# ESP32-S31 register map
Vendor: ESPRESSIF SYSTEMS (SHANGHAI) CO., LTD.; Series: ESP32 S-Series; File version: 1
CPU: RV32IMAFC r0p0, little endian, no MPU, FPU, 0 interrupt priority bits
Address unit: 32 bits
Registers are 32-bit, read-write, reset 0x0 unless marked. A register's access mark holds for its fields unless they carry their own. Offsets are from the block's base; [hi:lo] are bit positions; {n}, {i} and the like mark numbered series; 'fields as' and 'values as' point back to an identical list.

## USB_OTG_HS (part 5 of 5) — USB_OTG_HS Peripheral
Base 0x20300000
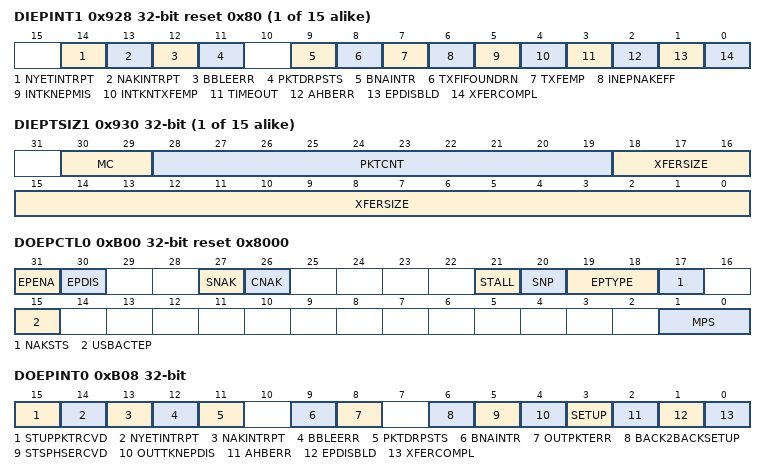
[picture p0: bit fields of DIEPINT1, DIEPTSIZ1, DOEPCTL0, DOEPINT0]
{0x908+0x20*i} DIEPINT{i} access per field reset 0x80 (i=1..15) — This register contains the interrupts for the IN Endpoint {i} of the Device controller. Note: This register exists for an endpoint i if the OTG_EP_DIR_i parameter is 0 or 1 for that endpoint.
  [14] NYETINTRPT rw — NYET Interrupt (NYETIntrpt) The core generates this interrupt when a NYET response is transmitted for a non isochronous OUT endpoint.
  [13] NAKINTRPT rw — NAK Interrupt (NAKInterrupt) The core generates this interrupt when a NAK is transmitted or received by the device. In case of isochronous IN endpoints the interrupt gets generated when a zero length packet is transmitted due to un-availability of data in the TXFifo.
  [12] BBLEERR rw — NAK Interrupt (BbleErr) The core generates this interrupt when babble is received for the endpoint.
  [11] PKTDRPSTS rw — Packet Drop Status (PktDrpSts) This bit indicates to the application that an ISOC OUT packet has been dropped. This bit does not have an associated mask bit and does not generate an interrupt. Dependency: This bit is valid in non Scatter/Gather DMA mode when periodic transfer interrupt feature is selected.
  [9] BNAINTR rw — BNA (Buffer Not Available) Interrupt (BNAIntr) This bit is valid only when Scatter/Gather DMA mode is enabled. The core generates this interrupt when the descriptor accessed is not ready for the Core to process, such as Host busy or DMA done.
  [8] TXFIFOUNDRN rw — Fifo Underrun (TxfifoUndrn) Applies to IN endpoints Only This bit is valid only If thresholding is enabled. The core generates this interrupt when it detects a transmit FIFO underrun condition for this endpoint.
  [7] TXFEMP ro — Transmit FIFO Empty (TxFEmp) This bit is valid only for IN endpoints This interrupt is asserted when the TxFIFO for this endpoint is either half or completely empty. The half or completely empty status is determined by the TxFIFO Empty Level bit in the Core AHB Configuration register (GAHBCFG.NPTxFEmpLvl)).
  [6] INEPNAKEFF rw — IN Endpoint NAK Effective (INEPNakEff) Applies to periodic IN endpoints only. This bit can be cleared when the application clears the IN endpoint NAK by writing to DIEPCTLn.CNAK. This interrupt indicates that the core has sampled the NAK bit Set (either by the application or by the core). The interrupt indicates that the IN endpoint NAK bit Set by the application has taken effect in the core. This interrupt does not guarantee that a NAK handshake is sent on the USB. A STALL bit takes priority over a NAK bit.
  [5] INTKNEPMIS rw — IN Token Received with EP Mismatch (INTknEPMis) Applies to non-periodic IN endpoints only. Indicates that the data in the top of the non-periodic TxFIFO belongs to an endpoint other than the one for which the IN token was received. This interrupt is asserted on the endpoint for which the IN token was received.
  [4] INTKNTXFEMP rw — IN Token Received When TxFIFO is Empty (INTknTXFEmp) Applies to non-periodic IN endpoints only. Indicates that an IN token was received when the associated TxFIFO (periodic/non-periodic) was empty. This interrupt is asserted on the endpoint for which the IN token was received.
  [3] TIMEOUT rw — Timeout Condition (TimeOUT) - In shared TX FIFO mode, applies to non-isochronous IN endpoints only. - In dedicated FIFO mode, applies only to Control IN endpoints. - In Scatter/Gather DMA mode, the TimeOUT interrupt is not asserted. Indicates that the core has detected a timeout condition on the USB for the last IN token on this endpoint.
  [2] AHBERR rw — AHB Error (AHBErr) Applies to IN and OUT endpoints. This is generated only in Internal DMA mode when there is an AHB error during an AHB read/write. The application can read the corresponding endpoint DMA address register to get the error address. For details, see AHB Error Handling in the Programming Guide.
  [1] EPDISBLD rw — Endpoint Disabled Interrupt (EPDisbld) Applies to IN and OUT endpoints. This bit indicates that the endpoint is disabled per the application's request.
  [0] XFERCOMPL rw — Transfer Completed Interrupt (XferCompl) Applies to IN and OUT endpoints. - When Scatter/Gather DMA mode is enabled -- For IN endpoint this field indicates that the requested data from the descriptor is moved from external system memory to internal FIFO. -- For OUT endpoint this field indicates that the requested data from the internal FIFO is moved to external system memory. This interrupt is generated only when the corresponding endpoint descriptor is closed, and the IOC bit for the corresponding descriptor is set. - When Scatter/Gather DMA mode is disabled, this field indicates that the programmed transfer is complete on the AHB as well as on the USB, for this endpoint.
{0x910+0x20*i} DIEPTSIZ{i} (i=1..15) — This register reflects the Transfer Size of the IN Endpoint {i} of the Device controller. Note: This register exists for an endpoint i if the OTG_EP_DIR_i parameter is 0 or 1 for that endpoint.
  [30:29] MC — MC Applies to IN endpoints only. For periodic IN endpoints, this field indicates the number of packets that must be transmitted per microframe on the USB. The core uses this field to calculate the data PID for isochronous IN endpoints. - 2'b01: 1 packet - 2'b10: 2 packets - 2'b11: 3 packets For non-periodic IN endpoints, this field is valid only in Internal DMA mode. It specifies the number of packets the core must fetchfor an IN endpoint before it switches to the endpoint pointed to by the Next Endpoint field of the Device Endpoint-n Control register (DIEPCTLn.NextEp)
  [28:19] PKTCNT — Packet Count (PktCnt) Indicates the total number of USB packets that constitute the Transfer Size amount of data for endpoint 0. This field is decremented every time a packet (maximum size or short packet) is read from the TxFIFO.
  [18:0] XFERSIZE — Transfer Size (XferSize) Indicates the transfer size in bytes for the endpoint. The core interrupts the application only after it has exhausted the transfer size amount of data. The transfer size can be Set to the maximum packet size of the endpoint, to be interrupted at the end of each packet. The core decrements this field every time a packet from the external memory is written to the TxFIFO.
{0x914+0x20*i} DIEPDMA{i} (i=1..15) — This register contains the DMA Address for the IN Endpoint {i} of the Device controller. Note: This register exists for an endpoint i if the OTG_EP_DIR_i parameter is 0 or 1 for that endpoint.
  [31:0] DMAADDR — Holds the start address of the external memory for storing or fetching endpoint data. Note: For control endpoints, this field stores control OUT data packets as well as SETUP transaction data packets. When more than three SETUP packets are received back-to-back, the SETUP data packet in the memory is overwritten. This register is incremented on every AHB transaction. The application can give only a DWORD-aligned address. - When Scatter/Gather DMA mode is not enabled, the application programs the start address value in this field. - When Scatter/Gather DMA mode is enabled, this field indicates the base pointer for the descriptor list.
{0x918+0x20*i} DTXFSTS{i} ro reset 0x400 (i=1..15) — This register reflects the status of the IN Endpoint Transmit FIFO Status Register {i} of the Device controller. Note: This register exists for an endpoint i if the OTG_EP_DIR_i parameter is 0 or 1 for that endpoint.
  [15:0] INEPTXFSPCAVAIL — IN Endpoint TxFIFO Space Avail (INEPTxFSpcAvail) Indicates the amount of free space available in the Endpoint TxFIFO. Values are in terms of 32-bit words. - 16'h0: Endpoint TxFIFO is full - 16'h1: 1 word available - 16'h2: 2 words available - 16'hn: n words available (where 0 n 32,768) - 16'h8000: 32,768 words available - Others: Reserved In DRD configurations (OTG_MODE = 0, 1, or 2) with dynamic fifo sizing feature enabled (OTG_DFIFO_DYNAMIC=1), the value of this field is, - the maximum value of (OTG_TX_HNPERIO_DFIFO_DEPTH, OTG_TX_DINEP_DFIFO_DEPTH_0) during reset, and - OTG_TX_DINEP_DFIFO_DEPTH_0, immediately after reset deassertion
{0x91C+0x20*i} DIEPDMAB{i} ro (i=1..15) — This register contains the DMA Buffer Address of the IN Endpoint {i} of the Device controller. Note: This register exists for an endpoint i if the OTG_EP_DIR_i parameter is 0 or 1 for that endpoint.
  [31:0] DMABUFFERADDR — Holds the current buffer address.This register is updated as and when the data transfer for the corresponding end point is in progress. This register is present only in Scatter/Gather DMA mode. Otherwise this field is reserved.
0xB00 DOEPCTL0 access per field reset 0x8000 — This register is used to control the characteristics of the OUT Endpoint 0 of the Device controller.
  [31] EPENA rw — Endpoint Enable (EPEna) - When Scatter/Gather DMA mode is enabled, for OUT endpoints this bit indicates that the descriptor structure and data buffer to receive data is setup. - When Scatter/Gather DMA mode is disabled (such as for buffer-pointer based DMA mode)this bit indicates that the application has allocated the memory to start receiving data from the USB. - The core clears this bit before setting any of the following interrupts on this endpoint: -- SETUP Phase Done -- Endpoint Disabled -- Transfer Completed Note: In DMA mode, this bit must be set for the core to transfer SETUP data packets into memory and it is not cleared on Transfer Completed interrupt of SETUP packet.
  [30] EPDIS ro — Endpoint Disable (EPDis) The application cannot disable control OUT endpoint 0.
  [27] SNAK rw — Set NAK (SNAK) A write to this bit sets the NAK bit for the endpoint. Using this bit, the application can control the transmission of NAK handshakes on an endpoint. The core can also set bit on a Transfer Completed interrupt, or after a SETUP is received on the endpoint.
  [26] CNAK rw — Clear NAK (CNAK) A write to this bit clears the NAK bit for the endpoint.
  [21] STALL rw — STALL Handshake (Stall) The application can only set this bit, and the core clears it, when a SETUP token is received for this endpoint. If a NAK bit or Global OUT NAK is Set along with this bit, the STALL bit takes priority. Irrespective of this bit's setting, the core always responds to SETUP data packets with an ACK handshake.
  [20] SNP rw — RESERVED
  [19:18] EPTYPE ro — Endpoint Type (EPType) Hardcoded to 2'b00 for control.
  [17] NAKSTS ro — NAK Status (NAKSts) Indicates the following: - 1'b0: The core is transmitting non-NAK handshakes based on the FIFO status. - 1'b1: The core is transmitting NAK handshakes on this endpoint. When either the application or the core sets this bit, the core stops receiving data, even If there is space in the RxFIFO to accommodate the incoming packet. Irrespective of this bit's setting, the core always responds to SETUP data packets with an ACK handshake.
  [15] USBACTEP ro — USB Active Endpoint (USBActEP) This bit is always set to 1, indicating that a control endpoint 0 is always active in all configurations and interfaces.
  [1:0] MPS ro — Maximum Packet Size (MPS) The maximum packet size for control OUT endpoint 0 is the same as what is programmed in control IN Endpoint 0. - 2'b00: 64 bytes - 2'b01: 32 bytes - 2'b10: 16 bytes - 2'b11: 8 bytes
0xB08 DOEPINT0 — This register contains the interrupts for the OUT Endpoint 0 of the Device controller.
  [15] STUPPKTRCVD — Setup Packet Received Applicable for Control OUT Endpoints in only in the Buffer DMA Mode Set by the controller, this bit indicates that this buffer holds 8 bytes of setup data. There is only one Setup packet per buffer. On receiving a Setup packet, the controller closes the buffer and disables the corresponding endpoint. The application has to re-enable the endpoint to receive any OUT data for the Control Transfer and reprogram the buffer start address. Note: Because of the above behavior, the controller can receive any number of back to back setup packets and one buffer for every setup packet is used. - 1'b0: No Setup packet received - 1'b1: Setup packet received Reset: 1'b0
  [14] NYETINTRPT — NYET Interrupt (NYETIntrpt) The core generates this interrupt when a NYET response is transmitted for a non isochronous OUT endpoint.
  [13] NAKINTRPT — NAK Interrupt (NAKInterrupt) The core generates this interrupt when a NAK is transmitted or received by the device. In case of isochronous IN endpoints the interrupt gets generated when a zero length packet is transmitted due to un-availability of data in the TXFifo.
  [12] BBLEERR — NAK Interrupt (BbleErr) The core generates this interrupt when babble is received for the endpoint.
  [11] PKTDRPSTS — Packet Drop Status (PktDrpSts) This bit indicates to the application that an ISOC OUT packet has been dropped. This bit does not have an associated mask bit and does not generate an interrupt. Dependency: This bit is valid in non Scatter/Gather DMA mode when periodic transfer interrupt feature is selected.
  [9] BNAINTR — BNA (Buffer Not Available) Interrupt (BNAIntr) This bit is valid only when Scatter/Gather DMA mode is enabled. The core generates this interrupt when the descriptor accessed is not ready for the core to process, such as Host busy or DMA done.
  [8] OUTPKTERR — OUT Packet Error (OutPktErr) Applies to OUT endpoints Only This interrupt is valid only when thresholding is enabled. This interrupt is asserted when the core detects an overflow or a CRC error for non-Isochronous OUT packet.
  [6] BACK2BACKSETUP — Back-to-Back SETUP Packets Received (Back2BackSETup) Applies to Control OUT endpoints only. This bit indicates that the core has received more than three back-to-back SETUP packets for this particular endpoint. For information about handling this interrupt,
  [5] STSPHSERCVD — Status Phase Received for Control Write (StsPhseRcvd) This interrupt is valid only for Control OUT endpoints. This interrupt is generated only after the core has transferred all the data that the host has sent during the data phase of a control write transfer, to the system memory buffer. The interrupt indicates to the application that the host has switched from data phase to the status phase of a Control Write transfer. The application can use this interrupt to ACK or STALL the Status phase, after it has decoded the data phase.
  [4] OUTTKNEPDIS — OUT Token Received When Endpoint Disabled (OUTTknEPdis) Applies only to control OUT endpoints. Indicates that an OUT token was received when the endpoint was not yet enabled. This interrupt is asserted on the endpoint for which the OUT token was received.
  [3] SETUP — SETUP Phase Done (SetUp) Applies to control OUT endpoints only. Indicates that the SETUP phase for the control endpoint is complete and no more back-to-back SETUP packets were received for the current control transfer. On this interrupt, the application can decode the received SETUP data packet.
  [2] AHBERR — AHB Error (AHBErr) Applies to IN and OUT endpoints. This is generated only in Internal DMA mode when there is an AHB error during an AHB read/write. The application can read the corresponding endpoint DMA address register to get the error address. For details, see AHB Error Handling section in the Programming Guide.
  [1] EPDISBLD — Endpoint Disabled Interrupt (EPDisbld) Applies to IN and OUT endpoints. This bit indicates that the endpoint is disabled per the application's request.
  [0] XFERCOMPL — Transfer Completed Interrupt (XferCompl) Applies to IN and OUT endpoints. When Scatter/Gather DMA mode is enabled - For IN endpoint this field indicates that the requested data from the descriptor is moved from external system memory to internal FIFO. - For OUT endpoint this field indicates that the requested data from the internal FIFO is moved to external system memory. This interrupt is generated only when the corresponding endpoint descriptor is closed, and the IOC bit for the corresponding descriptor is Set. Note: In DMA mode, this bit must be set for the core to transfer SETUP data packets into memory. When Scatter/Gather DMA mode is disabled, this field indicates that the programmed transfer is complete on the AHB as well as on the USB, for this endpoint.
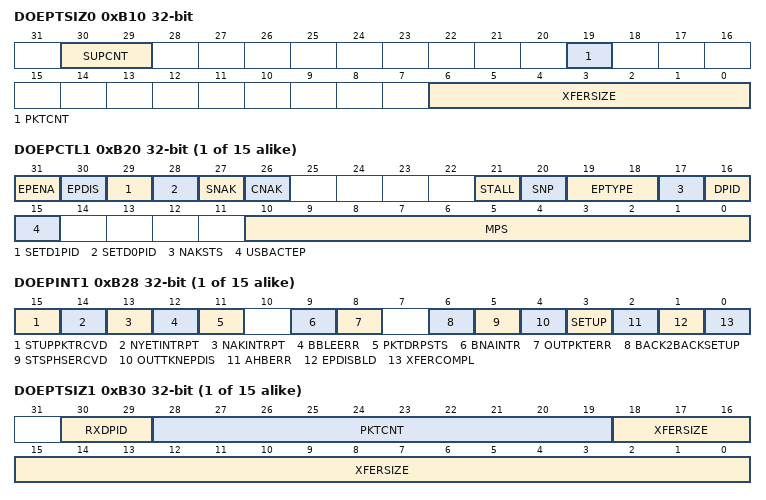
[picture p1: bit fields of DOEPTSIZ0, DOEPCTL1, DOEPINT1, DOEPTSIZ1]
0xB10 DOEPTSIZ0 — This register contains the Transfer Size for the OUT Endpoint 0 of the Device controller.
  [30:29] SUPCNT — SETUP Packet Count (SUPCnt) This field specifies the number of back-to-back SETUP data packets the endpoint can receive. - 2'b01: 1 packet - 2'b10: 2 packets - 2'b11: 3 packets
  [19] PKTCNT — Packet Count (PktCnt) This field is decremented to zero after a packet is written into the RxFIFO.
  [6:0] XFERSIZE — Transfer Size (XferSize) Indicates the transfer size in bytes for endpoint 0. The core interrupts the application only after it has exhausted the transfer size amount of data. The transfer size can be Set to the maximum packet size of the endpoint, to be interrupted at the end of each packet. The core decrements this field every time a packet is read from the RxFIFO and written to the external memory.
{0xB14+0x20*i} DOEPDMA{i} (i=0..15) — This register contains the DMA Address for the OUT Endpoint {i} of the Device controller.
  fields as DIEPDMA1
{0xB1C+0x20*i} DOEPDMAB{i} ro (i=0..15) — This register contains the DMA Buffer Address for the OUT Endpoint {i} of the Device controller.
  fields as DIEPDMAB1
{0xB00+0x20*i} DOEPCTL{i} access per field (i=1..15) — This register is used to control the characteristics of OUT Endpoint {i} of the Device controller.
  [31] EPENA rw — Endpoint Enable (EPEna) Applies to IN and OUT endpoints. When Scatter/Gather DMA mode is enabled, - For IN endpoints this bit indicates that the descriptor structure and data buffer with data ready to transmit is setup. - For OUT endpoint it indicates that the descriptor structure and data buffer to receive data is setup. When Scatter/Gather DMA mode is enabled such as for buffer-pointer based DMA mode: - For IN endpoints, this bit indicates that data is ready to be transmitted on the endpoint. - For OUT endpoints, this bit indicates that the application has allocated the memory to start receiving data from the USB. The core clears this bit before setting any of the following interrupts on this endpoint: - SETUP Phase Done - Endpoint Disabled - Transfer Completed Note: For control endpoints in DMA mode, this bit must be set for the controller to transfer SETUP data packets to the memory. This bit is not cleared on Transfer Completed interrupt of the SETUP packet.
  [30] EPDIS rw — Endpoint Disable (EPDis) Applies to IN and OUT endpoints. The application sets this bit to stop transmitting/receiving data on an endpoint, even before the transfer for that endpoint is complete. The application must wait for the Endpoint Disabled interrupt before treating the endpoint as disabled. The core clears this bit before setting the Endpoint Disabled interrupt. The application must set this bit only if Endpoint Enable is already set for this endpoint.
  [29] SETD1PID rw — Set DATA1 PID (SetD1PID) - Applies to interrupt and bulk IN and OUT endpoints only. - Writing to this field sets the Endpoint Data PID (DPID) field in this register to DATA1. - This field is applicable both for scatter-gather DMA mode and non scatter-gather DMA mode. Reset: 1'b0 Set Odd (micro)frame (SetOddFr) - Applies to isochronous IN and OUT endpoints only. - Writing to this field sets the even and odd (micro)frame (EO_FrNum) field to odd (micro)frame. Reset: 1'b0
  [28] SETD0PID rw — Set DATA0 PID (SetD0PID) - Applies to interrupt/bulk IN and OUT endpoints only. - Writing to this field sets the Endpoint Data PID (DPID) field in this register to DATA0. - This field is applicable both for Scatter/Gather DMA mode and non-Scatter/Gather DMA mode. Reset: 1'b0 In non-Scatter/Gather DMA mode: Set Even (micro)frame (SetEvenFr) - Applies to isochronous IN and OUT endpoints only. - Writing to this field sets the Even/Odd (micro)frame (EO_FrNum) field to even (micro)frame. - When Scatter/Gather DMA mode is enabled, this field is reserved. The frame number in which to send data is in the transmit descriptor structure. The frame in which to receive data is updated in receive descriptor structure. Reset: 1'b0
  [27] SNAK rw — Set NAK (SNAK) A write to this bit sets the NAK bit for the endpoint. Using this bit, the application can control the transmission of NAK handshakes on an endpoint. The core can also set this bit for an endpoint after a SETUP packet is received on that endpoint.
  [26] CNAK rw — Clear NAK (CNAK) A write to this bit clears the NAK bit for the endpoint.
  [21] STALL rw — STALL Handshake (Stall) Applies to non-control, non-isochronous IN and OUT endpoints only. The application sets this bit to stall all tokens from the USB host to this endpoint. If a NAK bit, Global Non-periodic IN NAK, or Global OUT NAK is set along with this bit, the STALL bit takes priority. Only the application can clear this bit, never the core. Applies to control endpoints only. The application can only set this bit, and the core clears it, when a SETUP token is received for this endpoint. If a NAK bit, Global Non-periodic IN NAK, or Global OUT NAK is set along with this bit, the STALL bit takes priority. Irrespective of this bit's setting, the core always responds to SETUP data packets with an ACK handshake.
  [20] SNP rw — RESERVED
  [19:18] EPTYPE rw — Endpoint Type (EPType) This is the transfer type supported by this logical endpoint. - 2'b00: Control - 2'b01: Isochronous - 2'b10: Bulk - 2'b11: Interrupt
  [17] NAKSTS ro — NAK Status (NAKSts) Indicates the following: - 1'b0: The core is transmitting non-NAK handshakes based on the FIFO status. - 1'b1: The core is transmitting NAK handshakes on this endpoint. When either the application or the core sets this bit: - The core stops receiving any data on an OUT endpoint, even if there is space in the RxFIFO to accommodate the incoming packet. - For non-isochronous IN endpoints: The core stops transmitting any data on an IN endpoint, even if there data is available in the TxFIFO. - For isochronous IN endpoints: The core sends out a zero-length data packet, even if there data is available in the TxFIFO. Irrespective of this bit's setting, the core always responds to SETUP data packets with an ACK handshake.
  [16] DPID ro — Endpoint Data PID (DPID) Applies to interrupt/bulk IN and OUT endpoints only. Contains the PID of the packet to be received or transmitted on this endpoint. The application must program the PID of the first packet to be received or transmitted on this endpoint, after the endpoint is activated. The applications use the SetD1PID and SetD0PID fields of this register to program either DATA0 or DATA1 PID. - 1'b0: DATA0 - 1'b1: DATA1 This field is applicable for both Scatter/Gather DMA mode and non-Scatter/Gather DMA mode. Reset: 1'b0 Even/Odd (Micro)Frame (EO_FrNum) In non-Scatter/Gather DMA mode: - Applies to isochronous IN and OUT endpoints only. - Indicates the (micro)frame number in which the core transmits/receives isochronous data for this endpoint. The application must program the even/odd (micro)frame number in which it intends to transmit/receive isochronous data for this endpoint using the SetEvnFr and SetOddFr fields in this register. -- 1'b0: Even (micro)frame -- 1'b1: Odd (micro)frame - When Scatter/Gather DMA mode is enabled, this field is reserved. The frame number in which to send data is provided in the transmit descriptor structure. The frame in which data is received is updated in receive descriptor structure. Reset: 1'b0
  [15] USBACTEP rw — USB Active Endpoint (USBActEP) Indicates whether this endpoint is active in the current configuration and interface. The core clears this bit for all endpoints (other than EP 0) after detecting a USB reset. After receiving the SetConfiguration and SetInterface commands, the application must program endpoint registers accordingly and set this bit.
  [10:0] MPS rw — Maximum Packet Size (MPS) The application must program this field with the maximum packet size for the current logical endpoint. This value is in bytes.
{0xB08+0x20*i} DOEPINT{i} (i=1..15) — This register contains the interrupts for the OUT Endpoint {i} of the Device controller.
  [15] STUPPKTRCVD — Setup Packet Received Applicable for Control OUT Endpoints in only in the Buffer DMA Mode Set by the controller, this bit indicates that this buffer holds 8 bytes of setup data. There is only one Setup packet per buffer. On receiving a Setup packet, the controller closes the buffer and disables the corresponding endpoint. The application has to re-enable the endpoint to receive any OUT data for the Control Transfer and reprogram the buffer start address. Note: Because of the above behavior, the controller can receive any number of back to back setup packets and one buffer for every setup packet is used. - 1'b0: No Setup packet received - 1'b1: Setup packet received Reset: 1'b0
  [14] NYETINTRPT — NYET Interrupt (NYETIntrpt) The core generates this interrupt when a NYET response is transmitted for a non isochronous OUT endpoint.
  [13] NAKINTRPT — NAK Interrupt (NAKInterrupt) The core generates this interrupt when a NAK is transmitted or received by the device. In case of isochronous IN endpoints the interrupt gets generated when a zero length packet is transmitted due to un-availability of data in the TXFifo.
  [12] BBLEERR — NAK Interrupt (BbleErr) The core generates this interrupt when babble is received for the endpoint.
  [11] PKTDRPSTS — Packet Drop Status (PktDrpSts) This bit indicates to the application that an ISOC OUT packet has been dropped. This bit does not have an associated mask bit and does not generate an interrupt. Dependency: This bit is valid in non Scatter/Gather DMA mode when periodic transfer interrupt feature is selected.
  [9] BNAINTR — BNA (Buffer Not Available) Interrupt (BNAIntr) This bit is valid only when Scatter/Gather DMA mode is enabled. The core generates this interrupt when the descriptor accessed is not ready for the Core to process, such as Host busy or DMA done
  [8] OUTPKTERR — OUT Packet Error (OutPktErr) Applies to OUT endpoints Only This interrupt is valid only when thresholding is enabled. This interrupt is asserted when the core detects an overflow or a CRC error for non-Isochronous OUT packet.
  [6] BACK2BACKSETUP — Back-to-Back SETUP Packets Received (Back2BackSETup) Applies to Control OUT endpoints only. This bit indicates that the core has received more than three back-to-back SETUP packets for this particular endpoint. For information about handling this interrupt,
  [5] STSPHSERCVD — Status Phase Received for Control Write (StsPhseRcvd) This interrupt is valid only for Control OUT endpoints. This interrupt is generated only after the core has transferred all the data that the host has sent during the data phase of a control write transfer, to the system memory buffer. The interrupt indicates to the application that the host has switched from data phase to the status phase of a Control Write transfer. The application can use this interrupt to ACK or STALL the Status phase, after it has decoded the data phase.
  [4] OUTTKNEPDIS — OUT Token Received When Endpoint Disabled (OUTTknEPdis) Applies only to control OUT endpoints. Indicates that an OUT token was received when the endpoint was not yet enabled. This interrupt is asserted on the endpoint for which the OUT token was received.
  [3] SETUP — SETUP Phase Done (SetUp) Applies to control OUT endpoints only. Indicates that the SETUP phase for the control endpoint is complete and no more back-to-back SETUP packets were received for the current control transfer. On this interrupt, the application can decode the received SETUP data packet.
  [2] AHBERR — AHB Error (AHBErr) Applies to IN and OUT endpoints. This is generated only in Internal DMA mode when there is an AHB error during an AHB read/write. The application can read the corresponding endpoint DMA address register to get the error address. For details, see AHB Error Handling section in the Programming Guide.
  [1] EPDISBLD — Endpoint Disabled Interrupt (EPDisbld) Applies to IN and OUT endpoints. This bit indicates that the endpoint is disabled per the application's request.
  [0] XFERCOMPL — Transfer Completed Interrupt (XferCompl) Applies to IN and OUT endpoints. - When Scatter/Gather DMA mode is enabled -- For IN endpoint this field indicates that the requested data from the descriptor is moved from external system memory to internal FIFO. -- For OUT endpoint this field indicates that the requested data from the internal FIFO is moved to external system memory. This interrupt is generated only when the corresponding endpoint descriptor is closed, and the IOC bit for the corresponding descriptor is Set. - When Scatter/Gather DMA mode is disabled, this field indicates that the programmed transfer is complete on the AHB as well as on the USB, for this endpoint.
{0xB10+0x20*i} DOEPTSIZ{i} access per field (i=1..15) — This register contains the Transfer Size for the OUT Endpoint {i} of the Device controller.
  [30:29] RXDPID ro — RxDPID Applies to isochronous OUT endpoints only. This is the data PID received in the last packet for this endpoint. - 2'b00: DATA0 - 2'b01: DATA2 - 2'b10: DATA1 - 2'b11: MDATA SETUP Packet Count (SUPCnt) Applies to control OUT Endpoints only. This field specifies the number of back-to-back SETUP data packets the endpoint can receive. - 2'b01: 1 packet - 2'b10: 2 packets - 2'b11: 3 packets
  [28:19] PKTCNT rw — Packet Count (PktCnt) This field is decremented to zero after a packet is written into the RxFIFO.
  [18:0] XFERSIZE rw — Transfer Size (XferSize) Indicates the transfer size in bytes for the endpoint. The core interrupts the application only after it has exhausted the transfer size amount of data. The transfer size can be Set to the maximum packet size of the endpoint, to be interrupted at the end of each packet. The core decrements this field every time a packet is read from the RxFIFO and written to the external memory.
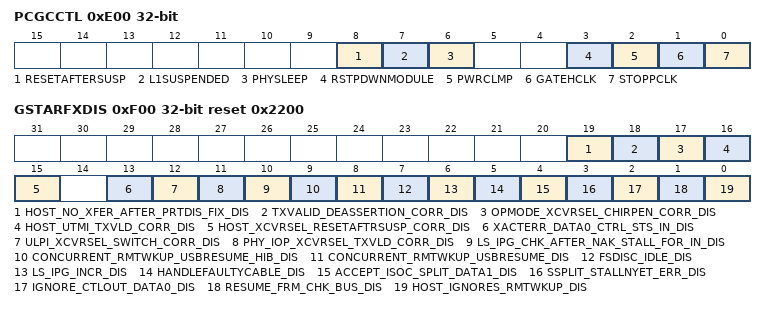
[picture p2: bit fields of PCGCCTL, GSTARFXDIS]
0xE00 PCGCCTL access per field — This register is used to control the Power and Clock Gating characteristics of the controller.
  [8] RESETAFTERSUSP rw — Reset after suspend Applicable in Partial power-down mode In partial power-down mode of operation, this bit needs to be set in host mode before clamp is removed if the host needs to issue reset after suspend. If this bit is not set, then the host issues resume after suspend. This bit is not applicable in device mode and non-partial power-down mode. In Hibernation mode, this bit needs to be set at RESTORE_POINT before PCGCCTL.EssRegRestored is set. In this case, PCGCCTL.restore_mode needs to be set to wait_restore.
  [7] L1SUSPENDED ro — L1 Deep Sleep Indicates that the PHY is in deep sleep when in L1 state.
  [6] PHYSLEEP ro — PHY In Sleep Indicates that the PHY is in Sleep State.
  [3] RSTPDWNMODULE rw — Reset Power-Down Modules (RstPdwnModule) This bit is valid only in Partial Power-Down mode. - The application sets this bit when the power is turned off. - The application clears this bit after the power is turned on and the PHY clock is up. Note: The R/W of all core registers are possible only when this bit is set to 1b0.
  [2] PWRCLMP rw — Power Clamp (PwrClmp) This bit is valid only in Partial Power-Down mode - The application sets this bit before the power is turned off to clamp the signals between the power-on modules and the power-off modules. - The application clears the bit to disable the clamping before the power is turned on.
  [1] GATEHCLK rw — Gate Hclk (GateHclk) - The application sets this bit to gate hclk to modules other than the AHB Slave and Master and wakeup logic when the USB is suspended or the session is not valid. - The application clears this bit when the USB is resumed or a new session starts.
  [0] STOPPCLK rw — Stop Pclk (StopPclk) - The application sets this bit to stop the PHY clock (phy_clk) when the USB is suspended, the session is not valid, or the device is disconnected. - The application clears this bit when the USB is resumed or a new session starts.
0xF00 GSTARFXDIS access per field reset 0x2200 — This register is used to disable STAR fixes added in the controller. The application can set the register fields to operate with the functionality before the fix was done.
  [19] HOST_NO_XFER_AFTER_PRTDIS_FIX_DIS rw — Disable the STAR fix added for correcting Host behavior when port is disabled. The RTL has been updated to not assert utmi_txvalid when the port is disabled. The application can set this register bit to 1'b1 to fall back to the original behavior of the controller. This bit must be programmed during the initial configuration of the controller and must not be modified later.
  [18] TXVALID_DEASSERTION_CORR_DIS rw — Disable the STAR fix added for correcting Txvalid deassertion on UTMI Interface when soft disconnect is done. The RTL has been updated to wait for utmi_txready and then de-assert the utmi_txvalid being driven by MAC DSSR when soft disconnect is done. The application can set this register bit to 1'b1 to fall back to the original behavior of the controller and change Txvalid without waiting for Txready. This bit must be programmed during the initial configuration of the controller and must not be modified later.
  [17] OPMODE_XCVRSEL_CHIRPEN_CORR_DIS rw — Disable the STAR fix added for correcting Opmode and XcvrSel on UTMI Interface when reset is detected in suspend state. In configurations with Battery charger support enabled (and GOTGCTL.ChirpEn programmed to 1), the RTL has been updated to wait for 1ms and then change the opmode and xcvrselect when reset is detected in the suspend state. The application can set this register bit to 1'b1 to fall back to the original behavior of the controller and change Opmode and XcvrSel without waiting for 1ms after reset detection. This bit must be programmed during the initial configuration of the controller and must not be modified later.
  [16] HOST_UTMI_TXVLD_CORR_DIS rw — Disable the correction to OpMode/XcvrSel/TermSel on UTMI Interface in Host mode. When HPRT.PrtRst is set by the application, the Host controller can change the Opmode, XcvrSel and TermSel while TxValid is still high (1'b1) during SOF transmission in 8-bit UTMI mode. This behavior of the controller has been corrected to handle port reset during SOF transmission. With the fix, the controller waits for Txvalid to go low (1'b0) and then changes the OpMode, XcvrSel and TermSel. The application can set this register bit to 1'b1 to fall back to the original behavior of the controller. This bit must be programmed during the initial configuration of the controller and must not be modified later.
  [15] HOST_XCVRSEL_RESETAFTRSUSP_CORR_DIS rw — Disable the STAR fix added for correcting XcvrSel on UTMI Interface in host mode. When host controller drives reset in power down suspend state, the behavior of XcvrSel has been corrected to drive the valid combination of XcvrSel (HS_XCVR) and TermSel (HS_TERM) on the UTMI interface. The application can set this register bit to 1'b1 to fall back to the original behavior of the Host controller driving XcvrSel (FS_XCVR) and TermSel (HS_TERM) when reset is driven to exit from power down state. This bit must be programmed during the initial configuration of the controller and must not be modified later.
  [13] XACTERR_DATA0_CTRL_STS_IN_DIS rw — Disable the STAR fix added for Host controller to report transaction error when DATA0 PID is received for CTRL STATUS IN transfer in DMA mode The application programs XactErr_DATA0_CTRL_STS_IN_dis=1 to allow the controller to respond with ACK for the incorrect DATA0 PID and then retry the control STATUS IN transfer until DATA1 PID is received. With XactErr_DATA0_CTRL_STS_IN_dis=0, the controller generates Transaction Error interrupt when the incorrect PID is received. This STAR fix is applicable only for Buffer DMA and Descriptor DMA modes. This bit must be programmed during the initial configuration of the controller and must not be modified later.
  [12] ULPI_XCVRSEL_SWITCH_CORR_DIS rw — Disable the STAR fix added for Host controller to increase the preamble transceiver select switch delay to accommodate time taken for ULPI function control write The application programs ULPI_xcvrsel_switch_corr_dis=1 to allow the controller to do back to back transceiver select switching within the duration required for a single ULPI function control write (around 5-6 ulpi_clk cycles). This can cause a corrupted packet to go on the bus since the ULPI wrapper may not be able to do the second ULPI functional update (register write) correctly. Hence it is recommended to program ULPI_xcvrsel_switch_corr_dis=0. With ULPI_xcvrsel_switch_corr_dis=0, the delay between transceiver select switch and txvalid assertion has also been increased for FS/LS mode to resolve PHY interop issues. This bit must be programmed during the initial configuration of the controller and must not be modified later.
  [11] PHY_IOP_XCVRSEL_TXVLD_CORR_DIS rw — Disable the STAR fix added for Host controller to increase the gap between utmi_xcvrselect switching and utmi_txvalid assertion in LS/FS mode The application programs PHY_IOp_xcvrsel_txvld_corr_dis=1 to allow the controller to assert utmi_txvalid 1 cycle after the utmi_xcvrselect switching. This can cause interop issues with SNPS PHY which requires at least 2 cycles of gap between the utmi_xcvrselect switch and the utmi_txvalid assertion. Hence it is recommended to program PHY_IOp_xcvrsel_txvld_corr_dis=0. This bit must be programmed during the initial configuration of the controller and must not be modified later.
  [10] LS_IPG_CHK_AFTER_NAK_STALL_FOR_IN_DIS rw — Disable the STAR fix added for Host controller to wait for IPG duration to send next token after receiving NAK/STALL for previous IN token with FS/LS device The application programs LS_IPG_chk_after_NAK_STALL_for_IN_dis=1 to allow the controller to send the next token without waiting for the interpacket gap duration after receiving a NAK/STALL from device for the previous IN token. This bit must be programmed during the initial configuration of the controller and must not be modified later.
  [9] CONCURRENT_RMTWKUP_USBRESUME_HIB_DIS rw — Disable the STAR fix added for Device controller to not hang when Remote Wakeup signalling clashes with Host resume The application can program Concurrent_Rmtwkup_USBResume_Hib_dis=1 to disable the fix. Note: With Concurrent_Rmtwkup_USBResume_Hib_dis=0, the STAR fix is enabled and the device controller does not hang when the remote wakeup clashes with host resume. After the remote wakeup programming is done, if there was no utmi_txready received from the PHY while the utmi_txvalid was asserted, then the controller detects the line K as the host resume and directly moves to the RESUMING state, along with de-asserting utmi_txvalid. This prevents the controller from hanging but also violates the UTMI spec requirement which states that utmi_txvalid must be de-asserted only after getting utmi_txready. Hence, if any misbehaviour is observed with this fix enabled, it is recommended to keep the fix disabled. This bit must be programmed during the initial configuration of the controller and must not be modified later. The fix is applicable only for Hibernation case.
  [8] CONCURRENT_RMTWKUP_USBRESUME_DIS rw — Disable the STAR fix added for Device controller to not start Remote Wakeup signalling when USB resume has already started The application programs Concurrent_Rmtwkup_USBResume_dis=1 to allow the controller to do remote wakeup signalling when USB resume has already started from the Host. This bit must be programmed during the initial configuration of the controller and must not be modified later.
  [7] FSDISC_IDLE_DIS rw — Disable the STAR fix added for Device controller to transition to IDLE state during FS device disconnect The application programs FSDisc_Idle_dis=1 to disable the Transmit/Receive state machine from moving to IDLE state when FS device disconnect happens. This bit must be programmed during the initial configuration of the controller and must not be modified later.
  [6] LS_IPG_INCR_DIS rw — Disable the STAR fix added for Host controller LS mode IPG increment from 2 LS bit times to 3 LS bit times The application programs LS_IPG_incr_dis=1 to disable the IPG increment from 2 to 3 LS bit times when host controller is operating in LS mode. This bit must be programmed during the initial configuration of the controller and must not be modified later.
  [5] HANDLEFAULTYCABLE_DIS rw — Disable the STAR fix added for Host controller to handle Faulty cable scenarios The application programs HandleFaultyCable_dis=1 to disable the host controller from reporting Port Babble error when the linestate is stuck at 1 (in FS mode) or 2 (in LS mode) due to a Faulty cable. This bit must be programmed during the initial configuration of the controller and must not be modified later.
  [4] ACCEPT_ISOC_SPLIT_DATA1_DIS rw — Disable the STAR fix added for Host controller to accept DATA1 PID from device for ISOC Split transfers The application programs Accept_Isoc_split_DATA1_dis=1 to disable the host controller from accepting DATA1 PID from device for ISOC Split transfers. This bit must be programmed during the initial configuration of the controller and must not be modified later.
  [3] SSPLIT_STALLNYET_ERR_DIS rw — Disable the STAR fix added for Host controller to flag error for SSPLIT STALL/NYET The application programs SSPLIT_STALLNYET_Err_dis=1 to disable the host controller from reporting transaction error for STALL/NYET received from device for SSPLIT transfer. This bit must be programmed during the initial configuration of the controller and must not be modified later.
  [2] IGNORE_CTLOUT_DATA0_DIS rw — Disable the STAR fix added for Device controller to reject DATA0 for the first Control OUT Data Phase and Control Status OUT Phase The application programs Ignore_CtlOUT_DATA0_dis=1 to disable the device controller from reporting transaction error when DATA0 PID is received from host for the first Control OUT Data Phase and Control Status OUT phase. This bit must be programmed during the initial configuration of the controller and must not be modified later.
  [1] RESUME_FRM_CHK_BUS_DIS rw — Disable the STAR fix added for Device controller to detect lineK and move to RESUMING state after the 50us pull-up delay ends The application programs Resume_frm_CHK_BUS_dis=1 to disable the device controller from detecting line K and transitioning to RESUMING state in the scenario where Host resume starts immediately after the 50us pull-up delay timer expires. This bit must be programmed during the initial configuration of the controller and must not be modified later.
  [0] HOST_IGNORES_RMTWKUP_DIS rw — Disable the STAR fix added for Device controller to go back to low power mode when Host ignores Remote wakeup The application programs Host_Ignores_RmtWkup_dis=1 to disable the device controller from going back to low power mode (SUSPENDED state) when the host ignores the remote wakeup signalling from the device and does not respond back with resume. This bit must be programmed during the initial configuration of the controller and must not be modified later.
